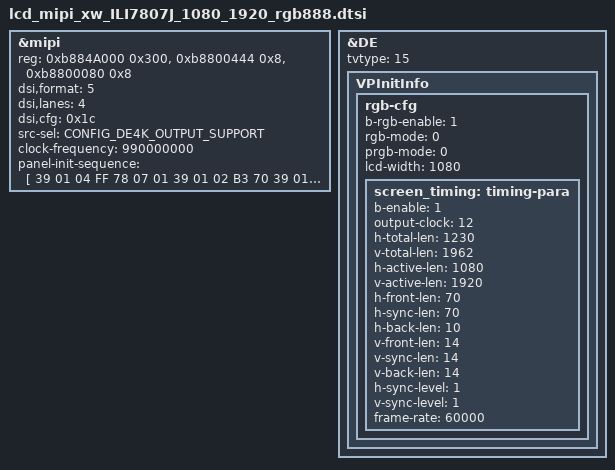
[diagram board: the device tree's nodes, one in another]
&mipi {
	reg = <0xb884A000 0x300>, <0xb8800444 0x8>,<0xb8800080 0x8>;

	/*
		* MIPI_COLOR_RGB565_0	=	0
		* MIPI_COLOR_RGB565_1	=	1
		* MIPI_COLOR_RGB565_2	=	2
		* MIPI_COLOR_RGB666_0	=	3
		* MIPI_COLOR_RGB666_1	=	4
		* MIPI_COLOR_RGB888	=	5
	*/
	dsi,format =<5>;

	dsi,lanes = <4>;

	/*
		* bit 6:5 MIPI_Virtual_Channel_Generic_ID
		* bit 4 :MIPI_CRC
		* bit 3 :MIPI_ECC
		* bit 2 :MIPI_Bus_Turn_request.
		* bit 1 :MIPI_EOTp
		* bit 0 :MIPI_EOTp
		*/

	dsi,cfg = <0x1c>;

	/*
		* 0: E_SRC_SEL_FXDE = 0
		* 1: E_SRC_SEL_4KDE
		* 2: E_SRC_SEL_HDMI_RX
		*/
	src-sel = <CONFIG_DE4K_OUTPUT_SUPPORT>;
	clock-frequency = <990000000>;
	// status = "okay";
};
&DE {
	tvtype = <15>;
	VPInitInfo {
		rgb-cfg{
			b-rgb-enable = <1>;
			/*
				* 0: MODE_PRGB
				* 1: MODE_SRGB
				*/
			rgb-mode = <0>;
			/*
				* 0: MODE_PRGB_888_10bit
				* 1: MODE_PRGB_666
				*/
			prgb-mode = <0>; 
			lcd-width = <1080>;
			screen_timing: timing-para {
				/* bool type, 0 or 1*/
				b-enable = <1>;
				/*
					* VPO_RGB_CLOCK_27M = 1,
					* VPO_RGB_CLOCK_33M = 2,
					* VPO_RGB_CLOCK_49M = 3,
					* VPO_RGB_CLOCK_66M = 4,
					* VPO_RGB_CLOCK_74M = 5,
					* VPO_RGB_CLOCK_85M = 6,
					* VPO_RGB_CLOCK_108M = 7,//H1600
					* VPO_RGB_CLOCK_6_6M = 8,
					* VPO_RGB_CLOCK_9M = 9,
					* VPO_RGB_CLOCK_39_6M = 10,
					* VPO_RGB_CLOCK_74_25M = 11,//H1600
					* VPO_RGB_CLOCK_148_5M = 12,//H1600
					* VPO_RGB_CLOCK_54M = 13,//H1600
					* VPO_RGB_CLOCK_132M = 14,//H1600
				*/
				output-clock = <12>;
				h-total-len = <1230>;
				v-total-len = <1962>;

				h-active-len = <1080>;
				v-active-len = <1920>;

				h-front-len = <70>;
				h-sync-len = <70>;
				h-back-len = <10>;

				v-front-len = <14>;
				v-sync-len = <14>;
				v-back-len = <14>;
				/* bool type, 0 or 1*/
				h-sync-level = <1>;
				/* bool type, 0 or 1*/
				v-sync-level = <1>;
				frame-rate = <60000>;
			};
		};
	};
};
&mipi{
panel-init-sequence = [
	39 01 04 FF 78 07 01
	39 01 02 B3 70
	39 01 02 B4 70
	39 01 02 4A 82
	39 01 02 4B 82
	39 01 02 A0 41
	39 01 02 50 30
	39 01 02 51 30
	39 01 02 A2 01
	39 01 02 A3 19
	39 01 02 A4 01
	39 01 02 A5 19
	39 01 02 22 06
	39 01 04 FF 78 07 02
	39 01 02 00 00
	39 01 02 01 0F
	39 01 02 02 00
	39 01 02 03 1C
	39 01 02 04 00
	39 01 02 05 33
	39 01 02 06 00
	39 01 02 07 49
	39 01 02 08 00
	39 01 02 09 5D
	39 01 02 0A 00
	39 01 02 0B 6E
	39 01 02 0C 00
	39 01 02 0D 7F
	39 01 02 0E 00
	39 01 02 0F 8F
	39 01 02 10 00
	39 01 02 11 9D
	39 01 02 12 00
	39 01 02 13 CE
	39 01 02 14 00
	39 01 02 15 F5
	39 01 02 16 01
	39 01 02 17 33
	39 01 02 18 01
	39 01 02 19 62
	39 01 02 1A 01
	39 01 02 1B AB
	39 01 02 1C 01
	39 01 02 1D E7
	39 01 02 1E 01
	39 01 02 1F E9
	39 01 02 20 02
	39 01 02 21 25
	39 01 02 22 02
	39 01 02 23 6E
	39 01 02 24 02
	39 01 02 25 9E
	39 01 02 26 02
	39 01 02 27 DD
	39 01 02 28 03
	39 01 02 29 05
	39 01 02 2A 03
	39 01 02 2B 34
	39 01 02 2C 03
	39 01 02 2D 43
	39 01 02 2E 03
	39 01 02 2F 51
	39 01 02 30 03
	39 01 02 31 60
	39 01 02 32 03
	39 01 02 33 72
	39 01 02 34 03
	39 01 02 35 84
	39 01 02 36 03
	39 01 02 37 96
	39 01 02 38 03
	39 01 02 39 A1
	39 01 02 3A 03
	39 01 02 3B E6
	39 01 02 3C 00
	39 01 02 3D 0F
	39 01 02 3E 00
	39 01 02 3F 1C
	39 01 02 40 00
	39 01 02 41 33
	39 01 02 42 00
	39 01 02 43 49
	39 01 02 44 00
	39 01 02 45 5D
	39 01 02 46 00
	39 01 02 47 6E
	39 01 02 48 00
	39 01 02 49 7F
	39 01 02 4A 00
	39 01 02 4B 8F
	39 01 02 4C 00
	39 01 02 4D 9D
	39 01 02 4E 00
	39 01 02 4F CE
	39 01 02 50 00
	39 01 02 51 F5
	39 01 02 52 01
	39 01 02 53 33
	39 01 02 54 01
	39 01 02 55 62
	39 01 02 56 01
	39 01 02 57 AB
	39 01 02 58 01
	39 01 02 59 E7
	39 01 02 5A 01
	39 01 02 5B E9
	39 01 02 5C 02
	39 01 02 5D 25
	39 01 02 5E 02
	39 01 02 5F 6E
	39 01 02 60 02
	39 01 02 61 9E
	39 01 02 62 02
	39 01 02 63 DD
	39 01 02 64 03
	39 01 02 65 05
	39 01 02 66 03
	39 01 02 67 34
	39 01 02 68 03
	39 01 02 69 43
	39 01 02 6A 03
	39 01 02 6B 51
	39 01 02 6C 03
	39 01 02 6D 60
	39 01 02 6E 03
	39 01 02 6F 72
	39 01 02 70 03
	39 01 02 71 84
	39 01 02 72 03
	39 01 02 73 96
	39 01 02 74 03
	39 01 02 75 A1
	39 01 02 76 03
	39 01 02 77 E6
	39 01 02 78 01
	39 01 02 79 01
	39 01 04 FF 78 07 03
	39 01 02 00 00
	39 01 02 01 0E
	39 01 02 02 00
	39 01 02 03 1B
	39 01 02 04 00
	39 01 02 05 33
	39 01 02 06 00
	39 01 02 07 49
	39 01 02 08 00
	39 01 02 09 5D
	39 01 02 0A 00
	39 01 02 0B 6E
	39 01 02 0C 00
	39 01 02 0D 7F
	39 01 02 0E 00
	39 01 02 0F 8E
	39 01 02 10 00
	39 01 02 11 9D
	39 01 02 12 00
	39 01 02 13 CD
	39 01 02 14 00
	39 01 02 15 F4
	39 01 02 16 01
	39 01 02 17 31
	39 01 02 18 01
	39 01 02 19 60
	39 01 02 1A 01
	39 01 02 1B A9
	39 01 02 1C 01
	39 01 02 1D E5
	39 01 02 1E 01
	39 01 02 1F E7
	39 01 02 20 02
	39 01 02 21 23
	39 01 02 22 02
	39 01 02 23 6E
	39 01 02 24 02
	39 01 02 25 9F
	39 01 02 26 02
	39 01 02 27 DD
	39 01 02 28 03
	39 01 02 29 05
	39 01 02 2A 03
	39 01 02 2B 34
	39 01 02 2C 03
	39 01 02 2D 42
	39 01 02 2E 03
	39 01 02 2F 50
	39 01 02 30 03
	39 01 02 31 60
	39 01 02 32 03
	39 01 02 33 71
	39 01 02 34 03
	39 01 02 35 82
	39 01 02 36 03
	39 01 02 37 93
	39 01 02 38 03
	39 01 02 39 9F
	39 01 02 3A 03
	39 01 02 3B E6
	39 01 02 3C 00
	39 01 02 3D 0E
	39 01 02 3E 00
	39 01 02 3F 1B
	39 01 02 40 00
	39 01 02 41 33
	39 01 02 42 00
	39 01 02 43 49
	39 01 02 44 00
	39 01 02 45 5D
	39 01 02 46 00
	39 01 02 47 6E
	39 01 02 48 00
	39 01 02 49 7F
	39 01 02 4A 00
	39 01 02 4B 8E
	39 01 02 4C 00
	39 01 02 4D 9D
	39 01 02 4E 00
	39 01 02 4F CD
	39 01 02 50 00
	39 01 02 51 F4
	39 01 02 52 01
	39 01 02 53 31
	39 01 02 54 01
	39 01 02 55 60
	39 01 02 56 01
	39 01 02 57 A9
	39 01 02 58 01
	39 01 02 59 E5
	39 01 02 5A 01
	39 01 02 5B E7
	39 01 02 5C 02
	39 01 02 5D 23
	39 01 02 5E 02
	39 01 02 5F 6E
	39 01 02 60 02
	39 01 02 61 9F
	39 01 02 62 02
	39 01 02 63 DD
	39 01 02 64 03
	39 01 02 65 05
	39 01 02 66 03
	39 01 02 67 34
	39 01 02 68 03
	39 01 02 69 42
	39 01 02 6A 03
	39 01 02 6B 50
	39 01 02 6C 03
	39 01 02 6D 60
	39 01 02 6E 03
	39 01 02 6F 71
	39 01 02 70 03
	39 01 02 71 82
	39 01 02 72 03
	39 01 02 73 93
	39 01 02 74 03
	39 01 02 75 9F
	39 01 02 76 03
	39 01 02 77 E6
	39 01 02 78 01
	39 01 02 79 01
	39 01 04 FF 78 07 04
	39 01 02 00 00
	39 01 02 01 11
	39 01 02 02 00
	39 01 02 03 1F
	39 01 02 04 00
	39 01 02 05 38
	39 01 02 06 00
	39 01 02 07 4F
	39 01 02 08 00
	39 01 02 09 63
	39 01 02 0A 00
	39 01 02 0B 75
	39 01 02 0C 00
	39 01 02 0D 86
	39 01 02 0E 00
	39 01 02 0F 96
	39 01 02 10 00
	39 01 02 11 A4
	39 01 02 12 00
	39 01 02 13 D4
	39 01 02 14 00
	39 01 02 15 FB
	39 01 02 16 01
	39 01 02 17 37
	39 01 02 18 01
	39 01 02 19 65
	39 01 02 1A 01
	39 01 02 1B AC
	39 01 02 1C 01
	39 01 02 1D E7
	39 01 02 1E 01
	39 01 02 1F E9
	39 01 02 20 02
	39 01 02 21 25
	39 01 02 22 02
	39 01 02 23 6E
	39 01 02 24 02
	39 01 02 25 9F
	39 01 02 26 02
	39 01 02 27 DD
	39 01 02 28 03
	39 01 02 29 05
	39 01 02 2A 03
	39 01 02 2B 34
	39 01 02 2C 03
	39 01 02 2D 41
	39 01 02 2E 03
	39 01 02 2F 50
	39 01 02 30 03
	39 01 02 31 5F
	39 01 02 32 03
	39 01 02 33 6F
	39 01 02 34 03
	39 01 02 35 7F
	39 01 02 36 03
	39 01 02 37 90
	39 01 02 38 03
	39 01 02 39 9B
	39 01 02 3A 03
	39 01 02 3B E6
	39 01 02 3C 00
	39 01 02 3D 11
	39 01 02 3E 00
	39 01 02 3F 1F
	39 01 02 40 00
	39 01 02 41 38
	39 01 02 42 00
	39 01 02 43 4F
	39 01 02 44 00
	39 01 02 45 63
	39 01 02 46 00
	39 01 02 47 75
	39 01 02 48 00
	39 01 02 49 86
	39 01 02 4A 00
	39 01 02 4B 96
	39 01 02 4C 00
	39 01 02 4D A4
	39 01 02 4E 00
	39 01 02 4F D4
	39 01 02 50 00
	39 01 02 51 FB
	39 01 02 52 01
	39 01 02 53 37
	39 01 02 54 01
	39 01 02 55 65
	39 01 02 56 01
	39 01 02 57 AC
	39 01 02 58 01
	39 01 02 59 E7
	39 01 02 5A 01
	39 01 02 5B E9
	39 01 02 5C 02
	39 01 02 5D 25
	39 01 02 5E 02
	39 01 02 5F 6E
	39 01 02 60 02
	39 01 02 61 9F
	39 01 02 62 02
	39 01 02 63 DD
	39 01 02 64 03
	39 01 02 65 05
	39 01 02 66 03
	39 01 02 67 34
	39 01 02 68 03
	39 01 02 69 41
	39 01 02 6A 03
	39 01 02 6B 50
	39 01 02 6C 03
	39 01 02 6D 5F
	39 01 02 6E 03
	39 01 02 6F 6F
	39 01 02 70 03
	39 01 02 71 7F
	39 01 02 72 03
	39 01 02 73 90
	39 01 02 74 03
	39 01 02 75 9B
	39 01 02 76 03
	39 01 02 77 E6
	39 01 02 78 01
	39 01 02 79 01
	39 01 04 FF 78 07 00
	05 78 01 11
	05 78 01 29
	];
};
